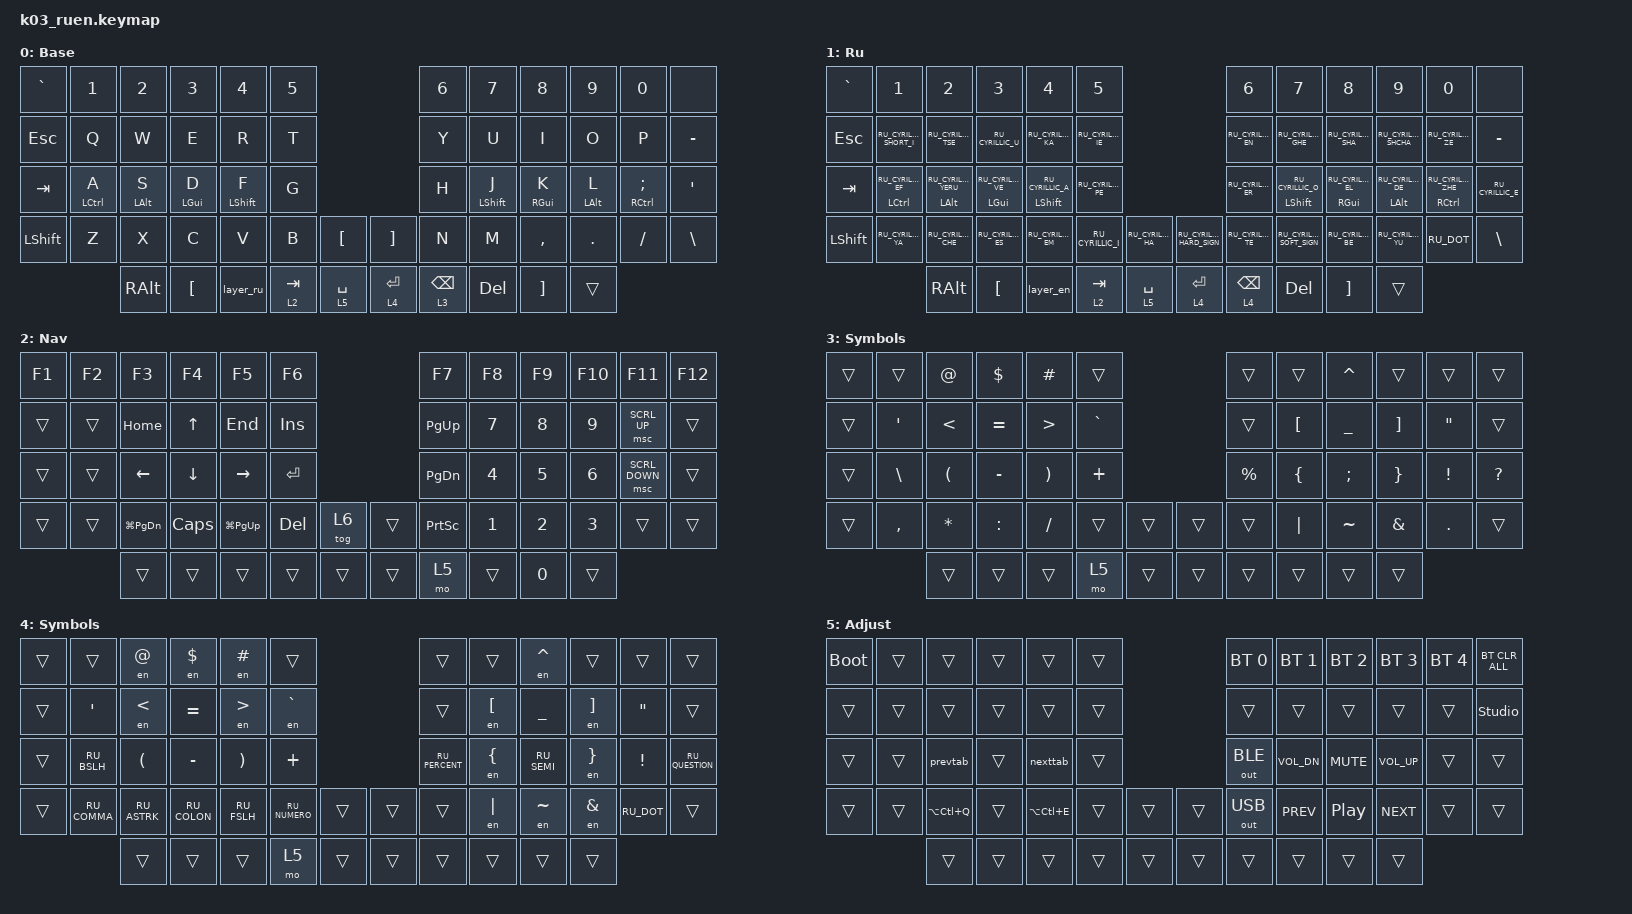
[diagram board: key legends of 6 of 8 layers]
#include "keys_ru.h"
#include <behaviors.dtsi>
#include <dt-bindings/zmk/bt.h>
#include <dt-bindings/zmk/keys.h>
#include <dt-bindings/zmk/outputs.h>
#include <dt-bindings/zmk/pointing.h>

&mt {
    quick-tap-ms = <200>;
    require-prior-idle-ms = <125>;
    flavor = "balanced";
};

&lt { quick-tap-ms = <200>; };

/ {
    behaviors {
        enc_vol: enc_vol {
            compatible = "zmk,behavior-sensor-rotate";
            label = "ENC_VOL";
            #sensor-binding-cells = <0>;
            bindings = <&kp C_VOL_UP>, <&kp C_VOL_DN>;
        };
    };

    combos {
        compatible = "zmk,combos";

        caps {
            bindings = <&caps_word>;
            key-positions = <25 34>;
        };
    };

    macros {
        to_ru: to_ru {
            compatible = "zmk,behavior-macro";
            #binding-cells = <0>;
            bindings = <&kp LS(LC(N2))>;
            label = "TO_RU";
            wait-ms = <0>;
            tap-ms = <30>;
        };

        to_en: to_en {
            compatible = "zmk,behavior-macro";
            #binding-cells = <0>;
            bindings = <&kp LS(LC(N1))>;
            label = "TO_EN";
            wait-ms = <0>;
            tap-ms = <30>;
        };

        layer_en: layer_en {
            compatible = "zmk,behavior-macro";
            #binding-cells = <0>;
            bindings = <&to 0 &to_en>;
            label = "LAYER_EN";
            wait-ms = <0>;
            tap-ms = <30>;
        };

        layer_ru: layer_ru {
            compatible = "zmk,behavior-macro";
            #binding-cells = <0>;
            bindings = <&to 1 &to_ru>;
            label = "LAYER_RU";
            tap-ms = <30>;
            wait-ms = <0>;
        };

        en: en {
            compatible = "zmk,behavior-macro-one-param";
            #binding-cells = <1>;
            bindings =
                <&to_en>,
                <&macro_press>,
                <&macro_param_1to1 &kp MACRO_PLACEHOLDER>,
                <&macro_pause_for_release>,
                <&macro_release>,
                <&macro_param_1to1 &kp MACRO_PLACEHOLDER>,
                <&macro_tap>,
                <&to_ru>;

            label = "EN";
            wait-ms = <0>;
            tap-ms = <30>;
        };

        nexttab: nexttab {
            compatible = "zmk,behavior-macro";
            #binding-cells = <0>;
            bindings =
                <&macro_press>,
                <&kp RCTRL>,
                <&macro_tap>,
                <&kp TAB>,
                <&macro_release>,
                <&kp RCTRL>;

            label = "NEXTTAB";
        };

        prevtab: prevtab {
            compatible = "zmk,behavior-macro";
            #binding-cells = <0>;
            bindings =
                <&macro_press>,
                <&kp RCTRL &kp LEFT_SHIFT>,
                <&macro_tap>,
                <&kp TAB>,
                <&macro_release>,
                <&kp RCTRL &kp LEFT_SHIFT>;

            label = "PREVTAB";
        };
    };

    keymap {
        compatible = "zmk,keymap";

        en {
            bindings = <
&kp GRAVE  &kp N1       &kp N2          &kp N3          &kp N4            &kp N5                                 &kp N6           &kp N7            &kp N8           &kp N9          &kp N0          &none
&kp ESC    &kp Q        &kp W           &kp E           &kp R             &kp T                                  &kp Y            &kp U             &kp I            &kp O           &kp P           &kp MINUS
&kp TAB    &mt LCTRL A  &mt LEFT_ALT S  &mt LEFT_GUI D  &mt LEFT_SHIFT F  &kp G                                  &kp H            &mt LEFT_SHIFT J  &mt RIGHT_GUI K  &mt LEFT_ALT L  &mt RCTRL SEMI  &kp SQT
&kp LSHFT  &kp Z        &kp X           &kp C           &kp V             &kp B      &kp LBKT       &kp RBKT     &kp N            &kp M             &kp COMMA        &kp DOT         &kp FSLH        &kp BACKSLASH
                        &kp RALT        &kp LBKT        &layer_ru         &lt 2 TAB  &lt 5 SPACE    &lt 4 ENTER  &lt 3 BACKSPACE  &kp DEL           &kp RBKT         &trans
            >;

            display-name = "Base";
            sensor-bindings = <&enc_vol>;
        };

        ru {
            display-name = "Ru";
            bindings = <
&kp GRAVE  &kp N1                    &kp N2                         &kp N3                       &kp N4                        &kp N5                                                               &kp N6              &kp N7                        &kp N8                        &kp N9                       &kp N0                     &none
&kp ESC    &kp RU_CYRILLIC_SHORT_I   &kp RU_CYRILLIC_TSE            &kp RU_CYRILLIC_U            &kp RU_CYRILLIC_KA            &kp RU_CYRILLIC_IE                                                   &kp RU_CYRILLIC_EN  &kp RU_CYRILLIC_GHE           &kp RU_CYRILLIC_SHA           &kp RU_CYRILLIC_SHCHA        &kp RU_CYRILLIC_ZE         &kp MINUS
&kp TAB    &mt LCTRL RU_CYRILLIC_EF  &mt LEFT_ALT RU_CYRILLIC_YERU  &mt LEFT_GUI RU_CYRILLIC_VE  &mt LEFT_SHIFT RU_CYRILLIC_A  &kp RU_CYRILLIC_PE                                                   &kp RU_CYRILLIC_ER  &mt LEFT_SHIFT RU_CYRILLIC_O  &mt RIGHT_GUI RU_CYRILLIC_EL  &mt LEFT_ALT RU_CYRILLIC_DE  &mt RCTRL RU_CYRILLIC_ZHE  &kp RU_CYRILLIC_E
&kp LSHFT  &kp RU_CYRILLIC_YA        &kp RU_CYRILLIC_CHE            &kp RU_CYRILLIC_ES           &kp RU_CYRILLIC_EM            &kp RU_CYRILLIC_I   &kp RU_CYRILLIC_HA    &kp RU_CYRILLIC_HARD_SIGN  &kp RU_CYRILLIC_TE  &kp RU_CYRILLIC_SOFT_SIGN     &kp RU_CYRILLIC_BE            &kp RU_CYRILLIC_YU           &kp RU_DOT                 &kp BACKSLASH
                                     &kp RALT                       &kp LBKT                     &layer_en                     &lt 2 TAB           &lt 5 SPACE           &lt 4 ENTER                &lt 4 BACKSPACE     &kp DEL                       &kp RBKT                      &trans
            >;

            sensor-bindings = <&enc_vol>;
        };

        nav {
            bindings = <
&kp F1  &kp F2  &kp F3             &kp F4    &kp F5         &kp F6                     &kp F7           &kp F8  &kp F9  &kp F10  &kp F11         &kp F12
&trans  &trans  &kp HOME           &kp UP    &kp END        &kp INS                    &kp PG_UP        &kp N7  &kp N8  &kp N9   &msc SCRL_UP    &trans
&trans  &trans  &kp LEFT           &kp DOWN  &kp RIGHT      &kp RET                    &kp PG_DN        &kp N4  &kp N5  &kp N6   &msc SCRL_DOWN  &trans
&trans  &trans  &kp LG(PAGE_DOWN)  &kp CAPS  &kp LG(PG_UP)  &kp DEL  &tog 6    &trans  &kp PRINTSCREEN  &kp N1  &kp N2  &kp N3   &trans          &trans
                &trans             &trans    &trans         &trans   &trans    &trans  &mo 5            &trans  &kp N0  &trans
            >;

            display-name = "Nav";
        };

        sym_en {
            bindings = <
&trans  &trans            &kp AT    &kp DLLR   &kp HASH  &trans                       &trans     &trans    &kp CARET  &trans    &trans             &trans
&trans  &kp SINGLE_QUOTE  &kp LT    &kp EQUAL  &kp GT    &kp GRAVE                    &trans     &kp LBKT  &kp UNDER  &kp RBKT  &kp DOUBLE_QUOTES  &trans
&trans  &kp BSLH          &kp LPAR  &kp MINUS  &kp RPAR  &kp PLUS                     &kp PRCNT  &kp LBRC  &kp SEMI   &kp RBRC  &kp EXCL           &kp QUESTION
&trans  &kp COMMA         &kp STAR  &kp COLON  &kp FSLH  &trans     &trans    &trans  &trans     &kp PIPE  &kp TILDE  &kp AMPS  &kp DOT            &trans
                          &trans    &trans     &trans    &mo 5      &trans    &trans  &trans     &trans    &trans     &trans
            >;

            display-name = "Symbols";
        };

        sym_ru {
            display-name = "Symbols";
            bindings = <
&trans  &trans            &en AT        &en DLLR      &en HASH     &trans                           &trans          &trans    &en CARET    &trans    &trans             &trans
&trans  &kp SINGLE_QUOTE  &en LT        &kp EQUAL     &en GT       &en GRAVE                        &trans          &en LBKT  &kp UNDER    &en RBKT  &kp DOUBLE_QUOTES  &trans
&trans  &kp RU_BSLH       &kp LPAR      &kp MINUS     &kp RPAR     &kp PLUS                         &kp RU_PERCENT  &en LBRC  &kp RU_SEMI  &en RBRC  &kp EXCL           &kp RU_QUESTION
&trans  &kp RU_COMMA      &kp RU_ASTRK  &kp RU_COLON  &kp RU_FSLH  &kp RU_NUMERO  &trans    &trans  &trans          &en PIPE  &en TILDE    &en AMPS  &kp RU_DOT         &trans
                          &trans        &trans        &trans       &mo 5          &trans    &trans  &trans          &trans    &trans       &trans
            >;
        };

        adj {
            bindings = <
&bootloader  &trans  &trans         &trans  &trans         &trans                    &bt BT_SEL 0  &bt BT_SEL 1  &bt BT_SEL 2      &bt BT_SEL 3  &bt BT_SEL 4  &bt BT_CLR_ALL
&trans       &trans  &trans         &trans  &trans         &trans                    &trans        &trans        &trans            &trans        &trans        &studio_unlock
&trans       &trans  &prevtab       &trans  &nexttab       &trans                    &out OUT_BLE  &kp C_VOL_DN  &kp C_MUTE        &kp C_VOL_UP  &trans        &trans
&trans       &trans  &kp LA(LC(Q))  &trans  &kp LA(LC(E))  &trans  &trans    &trans  &out OUT_USB  &kp C_PREV    &kp C_PLAY_PAUSE  &kp C_NEXT    &trans        &trans
                     &trans         &trans  &trans         &trans  &trans    &trans  &trans        &trans        &trans            &trans
            >;

            display-name = "Adjust";
        };

        game {
            display-name = "Game";
            bindings = <
&kp ESC    &kp N1  &kp N2     &kp N3     &kp N4  &kp N5                          &trans  &trans  &trans  &trans  &trans  &trans
&kp TAB    &kp Q   &kp E      &kp W      &kp R   &kp T                           &trans  &trans  &trans  &trans  &trans  &trans
&kp LCTRL  &kp A   &kp A      &kp S      &kp D   &kp G                           &trans  &trans  &trans  &trans  &trans  &trans
&kp LSHFT  &kp Z   &kp X      &kp C      &kp V   &kp B      &tog 6       &trans  &trans  &trans  &trans  &trans  &trans  &trans
                   &kp LSHFT  &kp LCTRL  &mo 7   &kp SPACE  &kp ENTER    &tog 7  &trans  &trans  &trans
            >;
        };

        // ── 8: GAME_NUM ───────────────────────────────────────────────────────

        game_num {
            display-name = "GNum";
            bindings = <
&kp GRAVE  &kp N1  &kp N2    &kp UP    &kp N4     &kp N5                    &trans  &trans  &trans  &trans  &trans  &trans
&trans     &kp N6  &kp LEFT  &kp DOWN  &kp RIGHT  &kp N3                    &trans  &trans  &trans  &trans  &trans  &trans
&trans     &kp F1  &kp F2    &kp F3    &kp F4     &kp F5                    &trans  &trans  &trans  &trans  &trans  &trans
&trans     &trans  &trans    &trans    &trans     &trans  &trans    &trans  &trans  &trans  &trans  &trans  &trans  &trans
                   &trans    &trans    &trans     &trans  &trans    &trans  &trans  &trans  &trans
            >;
        };
    };
};
